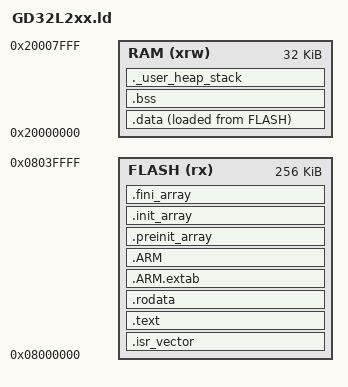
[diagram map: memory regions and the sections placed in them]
/*!
    \file    GD32_L2xx.ld
    \brief   linker script for the GD32_L2xx microcontroller

    \version 2025-11-17, V1.0.0, IN14_NIXIE_CLOCK_MODULE
*/

/*

/*
   Copyright 2025 Lukas Füreder

   Licensed under the Apache License, Version 2.0 (the "License");
   you may not use this file except in compliance with the License.
   You may obtain a copy of the License at

       http://www.apache.org/licenses/LICENSE-2.0

   Unless required by applicable law or agreed to in writing, software
   distributed under the License is distributed on an "AS IS" BASIS,
   WITHOUT WARRANTIES OR CONDITIONS OF ANY KIND, either express or implied.
   See the License for the specific language governing permissions and
   limitations under the License.
*/


ENTRY(RESET_HANDLER)

SYSTEMMEM_SIZE = 64K;    
SYSTEMMEM_START = 0x00000000;

FLASH_SIZE = 256K;    
FLASH_START = 0x08000000;
      
RAM_SIZE = 32K;
RAM_START = 0x20000000;  

/* Highest address of the user mode stack */
_estack = ORIGIN(RAM) + LENGTH(RAM);    /* end of RAM */
/* Generate a link error if heap and stack don't fit into RAM */
_Min_Heap_Size = 0x200;      /* required amount of heap  */
_Min_Stack_Size = 0x400; /* required amount of stack */

/* Specify the memory areas */
MEMORY
{
    /*SYSTEMMEM (rx)  : ORIGIN = SYSTEMMEM_START, LENGTH = SYSTEMMEM_SIZE */
    FLASH (rx)      : ORIGIN = FLASH_START, LENGTH = FLASH_SIZE
    RAM (xrw)      : ORIGIN = RAM_START, LENGTH = RAM_SIZE 
}

SECTIONS 
{
 /* The startup code goes first into SYSTEMMEM */
  .isr_vector :
  {
    . = ALIGN(8);
    KEEP(*(.isr_vector)) /* Startup code */
    . = ALIGN(8);
  } >FLASH

  /* The program code and other data goes into FLASH */
  .text :
  {
    . = ALIGN(8);
    *(.text)           /* .text sections (code) */
    *(.text*)          /* .text* sections (code) */
    *(.glue_7)         /* glue arm to thumb code */
    *(.glue_7t)        /* glue thumb to arm code */
    *(.eh_frame)

    KEEP (*(.init))
    KEEP (*(.fini))

    . = ALIGN(8);
    _etext = .;        /* define a global symbols at end of code */
  } >FLASH

  /* Initialized data sections goes into RAM, load LMA copy after code */
  .data : 
  {
    . = ALIGN(8);
    _sdata = .;        /* create a global symbol at data start */
    *(.data)           /* .data sections */
    *(.data*)          /* .data* sections */

    . = ALIGN(8);
    _edata = .;        /* define a global symbol at data end */
  } >RAM AT> FLASH
  
  /* Constant data goes into FLASH */
  .rodata :
  {
    . = ALIGN(8);
    *(.rodata)         /* .rodata sections (constants, strings, etc.) */
    *(.rodata*)        /* .rodata* sections (constants, strings, etc.) */
    . = ALIGN(8);
  } >FLASH

  .ARM.extab   : 
  { 
  . = ALIGN(8);
  *(.ARM.extab* .gnu.linkonce.armextab.*)
  . = ALIGN(8);
  } >FLASH
  .ARM : {
	. = ALIGN(8);
    __exidx_start = .;
    *(.ARM.exidx*)
    __exidx_end = .;
	. = ALIGN(8);
  } >FLASH

  .preinit_array     :
  {
	. = ALIGN(8);
    PROVIDE_HIDDEN (__preinit_array_start = .);
    KEEP (*(.preinit_array*))
    PROVIDE_HIDDEN (__preinit_array_end = .);
	. = ALIGN(8);
  } >FLASH
  
  .init_array :
  {
	. = ALIGN(8);
    PROVIDE_HIDDEN (__init_array_start = .);
    KEEP (*(SORT(.init_array.*)))
    KEEP (*(.init_array*))
    PROVIDE_HIDDEN (__init_array_end = .);
	. = ALIGN(8);
  } >FLASH
  .fini_array :
  {
	. = ALIGN(8);
    PROVIDE_HIDDEN (__fini_array_start = .);
    KEEP (*(SORT(.fini_array.*)))
    KEEP (*(.fini_array*))
    PROVIDE_HIDDEN (__fini_array_end = .);
	. = ALIGN(8);
  } >FLASH

  /* used by the startup to initialize data */
  _sidata = LOADADDR(.data);

  /* Uninitialized data section */
  . = ALIGN(4);
  .bss :
  {
    /* This is used by the startup in order to initialize the .bss secion */
    _sbss = .;         /* define a global symbol at bss start */
    __bss_start__ = _sbss;
    *(.bss)
    *(.bss*)
    *(COMMON)

    . = ALIGN(4);
    _ebss = .;         /* define a global symbol at bss end */
    __bss_end__ = _ebss;
  } >RAM

  /* User_heap_stack section, used to check that there is enough RAM left */
  ._user_heap_stack :
  {
    . = ALIGN(8);
    PROVIDE ( end = . );
    PROVIDE ( _end = . );
    . = . + _Min_Heap_Size;
    . = . + _Min_Stack_Size;
    . = ALIGN(8);
  } >RAM

  

  /* Remove information from the standard libraries */
  /DISCARD/ :
  {
    libc.a ( * )
    libm.a ( * )
    libgcc.a ( * )
  }

  .ARM.attributes 0 : { *(.ARM.attributes) }
}
